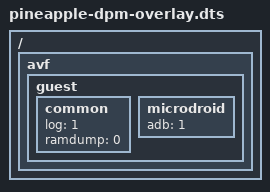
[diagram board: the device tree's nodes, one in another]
/dts-v1/;
/plugin/;

/ {
	fragment@avf {
		target-path = "/";
		__overlay__ {
			avf {
				guest {
					common {
						log=<1>;
						ramdump=<0>;
					};
					microdroid {
						adb=<1>;
					};
				};
			};
		};
	};

	__fixups__ {
	};
};
